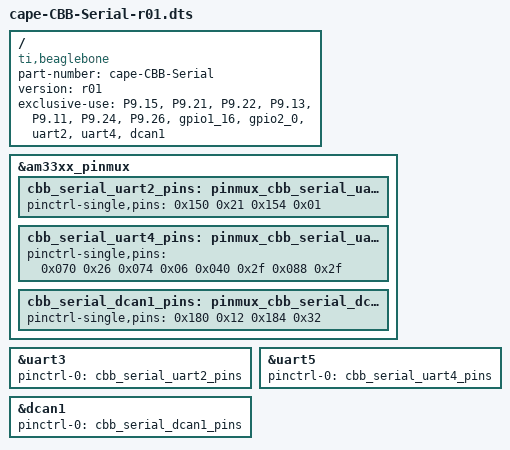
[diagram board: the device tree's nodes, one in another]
/* cape-CBB-Serial-r01.dts
 * Written by Alexander Hiam <hiamalexander@gmail.com>
 * for Logic Supply - http://logicsupply.com
 * Jan 28, 2014
 *
 * This is the Device Tree overlay for the CBB-Serial BeagleBone and
 * BeagleBone Black cape. It will enable the UART2, UART4 and DCAN1
 * interfaces, as well as mux GPIO1_16 for userspace control for
 * using software control of the RS485 receiver/driver enable.
 *
 * Note: the BeagleBone Black has GPIO1_16 tied to GPIO2_0 (which
 * is not exposed on the header), so this overlay muxes and controls
 * both pins.
 *
 * Copyright (c) 2014 - Logic Supply (http://logicsupply.com)
 * This program is free software; you can redistribute it and/or modify
 * it under the terms of the GNU General Public License version 2 as
 * published by the Free Software Foundation.
 */

/dts-v1/;
/plugin/;

/{
	compatible = "ti,beaglebone", "ti,beaglebone-black", "ti,beaglebone-green";

  part-number = "cape-CBB-Serial";
  version = "r01";

  /* state the resources this cape uses */
  exclusive-use =
    /* the pin header uses */
    "P9.15", /* GPIO1_16 */

    "P9.21", /* uart2_txd */
    "P9.22", /* uart2_rxd */

    "P9.13", /* uart4_txd */
    "P9.11", /* uart4_rxd */

    "P9.24", /* dcan1_rx */
    "P9.26", /* dcan1_tx */

    /* the hardware IP uses */
    "gpio1_16",
    "gpio2_0",
    "uart2",
    "uart4",
    "dcan1";

  fragment@0 {
    target = <&am33xx_pinmux>;
    __overlay__ {

      cbb_serial_uart2_pins: pinmux_cbb_serial_uart2_pins {
        pinctrl-single,pins = <
          0x150 0x21 /* spi0_sclk - RX_ENABLED | MODE6 (UART2 RX) */
          0x154 0x01 /* spi0_d0 - MODE6 (UART2 TX) */
        >;
      };

      cbb_serial_uart4_pins: pinmux_cbb_serial_uart4_pins {
        pinctrl-single,pins = <
          0x070 0x26 /* gpmc_wait0 - RX_ENABLED | MODE6 (UART4 RX) */
          0x074 0x06 /* gpmc_wpn - MODE6 (UART4 TX) */
          0x040 0x2f /* gpmc_a0 - pull disabled | MODE7 (GPIO1_16) */
          0x088 0x2f /* gpmc_csn3 - pull disabled | MODE7 (GPIO2_0) */
        >;
      };

      cbb_serial_dcan1_pins: pinmux_cbb_serial_dcan1_pins {
        pinctrl-single,pins = <
          0x180 0x12 /* uart1_rxd - PULLUP | MODE2 (DCAN TX) */
          0x184 0x32 /* uart1_txd - RX_ENABLED | PULLUP | MODE2 (DCAN1 RX) */
        >;
      };
    };
  };

  fragment@1 {
    target = <&uart3>;
    __overlay__ {
      status = "okay";
      pinctrl-names = "default";
      pinctrl-0 = <&cbb_serial_uart2_pins>;
    };
  };

  fragment@2 {
    target = <&uart5>;
    __overlay__ {
      status = "okay";
      pinctrl-names = "default";
      pinctrl-0 = <&cbb_serial_uart4_pins>;
    };
  };

  fragment@3 {
    target = <&dcan1>;
    __overlay__ {
      status = "okay";
      pinctrl-names = "default";
      pinctrl-0 = <&cbb_serial_dcan1_pins>;
    };
  };
};
